# STM32H533 register map
File version: 1.3
CPU: CM33 r0p0, little endian, MPU, FPU, 4 interrupt priority bits
Registers are 32-bit, read-write, reset 0x0 unless marked. A register's access mark holds for its fields unless they carry their own. Offsets are from the block's base; [hi:lo] are bit positions; {n}, {i} and the like mark numbered series; 'fields as' and 'values as' point back to an identical list.

## SAU — Security Attribution Unit -- present only when the Security Extension (TrustZone) is implemented; absent entirely on a Non-secure-only/single-state part. RNR/RBAR/RLAR are further optional within that: only present when __SAUREGION_PRESENT=1, i.e. the implementation has at least one programmable SAU region (a part can implement the Security Extension with the whole memory map fixed Secure/Non-secure by IDAU alone and no SAU regions at all). Verified against CMSIS_6 core_cm23.h/core_cm33.h (identical on both profiles). SFSR/SFAR are modeled once, under SCB, since SAU_Type and SCB_Type both expose the same physical registers at the same address on Mainline -- CMSIS_6 now says so explicitly (SAU_Type's own SFSR/SFAR are commented "deprecated: use SCB->SFSR"/"SCB->SFAR"); Baseline has neither (no SecureFault handler exists there).
Base 0xE000EDD0
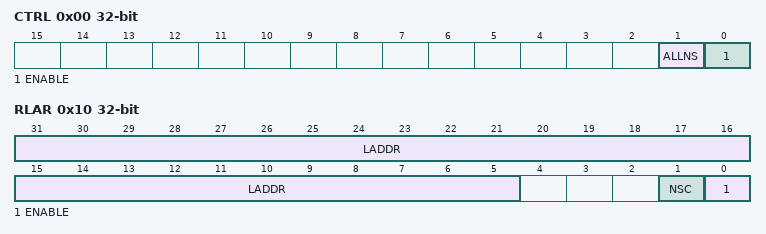
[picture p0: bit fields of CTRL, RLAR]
0x00 CTRL — SAU Control Register
  [1] ALLNS — All Non-secure -- forces the whole memory map Non-secure when SAU is disabled
  [0] ENABLE
0x04 TYPE ro — SAU Type Register
  [7:0] SREGION — Number of implemented SAU regions
0x08 RNR — SAU Region Number Register -- only present if __SAUREGION_PRESENT
  [7:0] REGION
0x0C RBAR — SAU Region Base Address Register -- only present if __SAUREGION_PRESENT
  [31:5] BADDR — Base address, 32-byte aligned
0x10 RLAR — SAU Region Limit Address Register -- only present if __SAUREGION_PRESENT
  [31:5] LADDR — Limit address, 32-byte aligned
  [1] NSC — Non-secure Callable
  [0] ENABLE

## SCnSCB — System Control and ID Registers not in the SCB address range: ICTR (Interrupt Controller Type Register), ACTLR (Auxiliary Control Register), and CPPWR (Coprocessor Power Control -- new in ARMv8-M Mainline). Verified against CMSIS_6 core_cm33.h. Absent entirely on ARMv8-M Baseline, same as ARMv6-M.
Base 0xE000E000
0x04 ICTR ro — Interrupt Controller Type Register
  [3:0] INTLINESNUM — (Number of 32-interrupt NVIC banks implemented) - 1: total external interrupts = (INTLINESNUM+1)*32
0x08 ACTLR — Auxiliary Control Register -- wholly IMPLEMENTATION DEFINED by the architecture, same as on ARMv7-M -- deliberately left with no fields.
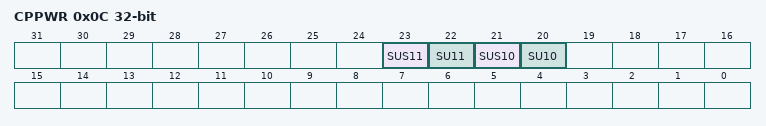
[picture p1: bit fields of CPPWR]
0x0C CPPWR — Coprocessor Power Control Register -- new in ARMv8-M Mainline; only meaningful if an FPU (coprocessors 10/11) is implemented.
  [23] SUS11 — Coprocessor 11 (FPU) power enable in Sleep -- only meaningful if an FPU is implemented
  [22] SU11 — Coprocessor 11 (FPU) power enable -- only meaningful if an FPU is implemented
  [21] SUS10 — Coprocessor 10 (FPU) power enable in Sleep -- only meaningful if an FPU is implemented
  [20] SU10 — Coprocessor 10 (FPU) power enable -- only meaningful if an FPU is implemented

## SysTick — SysTick Timer. Identical register set on every Cortex-M core (ARMv6-M through current ARMv8-M).
Base 0xE000E010
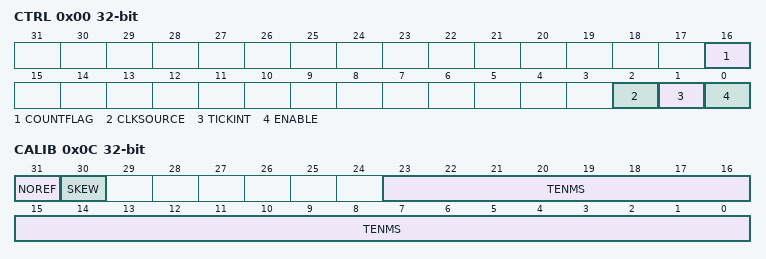
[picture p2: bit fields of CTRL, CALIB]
0x00 CTRL — SysTick Control and Status Register
  [16] COUNTFLAG ro, [2] CLKSOURCE, [1] TICKINT, [0] ENABLE
0x04 LOAD — SysTick Reload Value Register
  [23:0] RELOAD
0x08 VAL — SysTick Current Value Register. Any write clears it to 0 and clears COUNTFLAG.
  [23:0] CURRENT
0x0C CALIB ro — SysTick Calibration Value Register
  [31] NOREF, [30] SKEW, [23:0] TENMS

## TIM6 — TIM6 address block description
Base 0x40001000
Same registers: TIM6_S 0x50001000
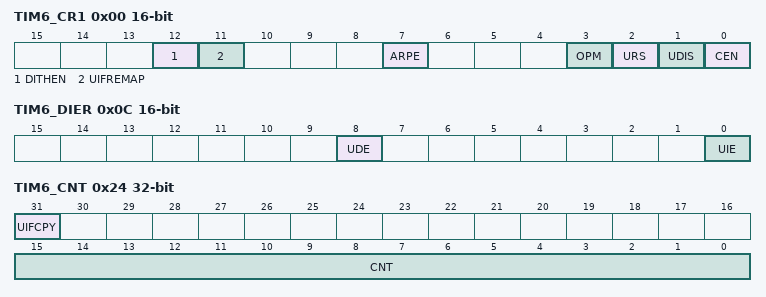
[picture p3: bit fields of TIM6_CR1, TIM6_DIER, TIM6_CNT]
0x00 TIM6_CR1 16-bit — TIM6 control register 1
  [12] DITHEN — Dithering enable
    0=Dithering disabled; 1=Dithering enabled
  [11] UIFREMAP — UIF status bit remapping
    0=No remapping; 1=Remapping enabled
  [7] ARPE — Auto-reload preload enable
    0=TIMx_ARR register is not buffered; 1=TIMx_ARR register is buffered
  [3] OPM — One-pulse mode
    0=Counter is not stopped at update event; 1=Counter stops counting at the next update event (clearing the CEN bit)
  [2] URS — Update request source
    0=Any of the following events generates an update interrupt or DMA request if enabled; 1=Only counter overflow/underflow generates an update interrupt or DMA request if enabled
  [1] UDIS — Update disable
    0=UEV enabled; 1=UEV disabled
  [0] CEN — Counter enable
    0=Counter disabled; 1=Counter enabled
0x04 TIM6_CR2 16-bit — TIM6 control register 2
  [6:4] MMS — Master mode selection
    0=Reset - the UG bit from the TIMx_EGR register is used as a trigger output (tim_trgo); 1=Enable - the Counter enable signal, tim_cnt_en, is used as a trigger output (tim_trgo); 2=Update - The update event is selected as a trigger output (tim_trgo)
0x0C TIM6_DIER 16-bit — TIM6 DMA/Interrupt enable register
  [8] UDE — Update DMA request enable
    0=Update DMA request disabled; 1=Update DMA request enabled
  [0] UIE — Update interrupt enable
    0=Update interrupt disabled; 1=Update interrupt enabled
0x10 TIM6_SR 16-bit — TIM6 status register
  [0] UIF — Update interrupt flag
    0=No update occurred; 1=Update interrupt pending
0x14 TIM6_EGR 16-bit wo — TIM6 event generation register
  [0] UG — Update generation
    0=No action; 1=Re-initializes the timer counter and generates an update of the registers
0x24 TIM6_CNT — TIM6 counter
  [31] UIFCPY ro — UIF copy
  [15:0] CNT — Counter value
0x28 TIM6_PSC 16-bit — TIM6 prescaler
  [15:0] PSC — Prescaler value
0x2C TIM6_ARR reset 0xFFFF — TIM6 auto-reload register
  [19:0] ARR — Auto-reload value

## TIM7 — TIM7 address block description
Base 0x40001400
Same registers: TIM7_S 0x50001400
Registers as TIM6 (with TIM6 read as TIM7).

## USBSRAM — USBSRAM address block description
Base 0x40016400
Same registers: USBSRAM_S 0x50016400
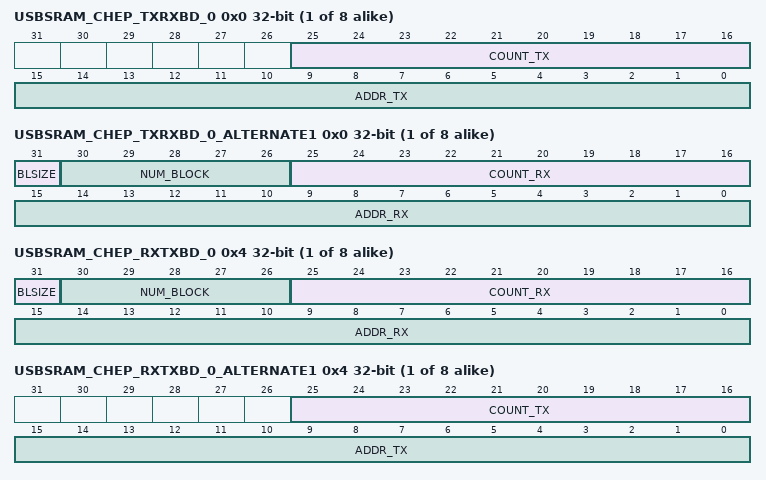
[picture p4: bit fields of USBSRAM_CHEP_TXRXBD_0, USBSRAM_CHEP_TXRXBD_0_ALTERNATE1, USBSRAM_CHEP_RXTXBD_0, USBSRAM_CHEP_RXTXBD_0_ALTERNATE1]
{0x0+8i} USBSRAM_CHEP_TXRXBD_{i} reset not defined (i=0..7) — Channel/endpoint transmit buffer descriptor {i}
  [25:16] COUNT_TX — Transmission byte count
  [15:0] ADDR_TX — Transmission buffer address
{0x0+8i} USBSRAM_CHEP_TXRXBD_{i}_ALTERNATE1 reset not defined (alternate view of USBSRAM_CHEP_TXRXBD_{i}) (i=0..7) — Channel/endpoint receive buffer descriptor {i}
  [31] BLSIZE — Block size
  [30:26] NUM_BLOCK — Number of blocks
  [25:16] COUNT_RX ro — Reception byte count
  [15:0] ADDR_RX — Reception buffer address
{0x4+8i} USBSRAM_CHEP_RXTXBD_{i} reset not defined (i=0..7) — Channel/endpoint receive buffer descriptor {i}
  fields as USBSRAM_CHEP_TXRXBD_0_ALTERNATE1
{0x4+8i} USBSRAM_CHEP_RXTXBD_{i}_ALTERNATE1 reset not defined (alternate view of USBSRAM_CHEP_RXTXBD_{i}) (i=0..7) — Channel/endpoint transmit buffer descriptor {i}
  fields as USBSRAM_CHEP_TXRXBD_0

## VREFBUF — VREFBUF address block description
Base 0x44007400
Same registers: VREFBUF_S 0x54007400
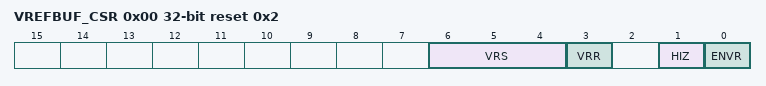
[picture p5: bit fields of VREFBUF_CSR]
0x00 VREFBUF_CSR reset 0x2 — VREFBUF control and status register
  [6:4] VRS — Voltage reference scale
  [3] VRR ro — Voltage reference buffer ready
    0=the voltage reference buffer output is not ready; 1=the voltage reference buffer output reached the requested level
  [1] HIZ — High impedance mode
    0=Vless thansub>REF+less than/sub> pin is internally connected to the voltage reference buffer output; 1=Vless thansub>REF+less than/sub> pin is high impedance
  [0] ENVR — Voltage reference buffer mode enable
    0=Internal voltage reference mode disable (external voltage reference mode); 1=Internal voltage reference mode (reference buffer enable or hold mode) enable
0x04 VREFBUF_CCR (reset mask 0xFFFFFF00) — VREFBUF calibration control register
  [5:0] TRIM — Trimming code

## WWDG — WWDG address block description
Base 0x40002C00
Same registers: WWDG_S 0x50002C00
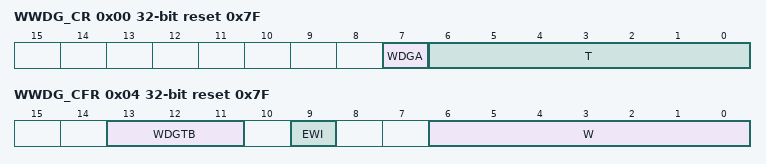
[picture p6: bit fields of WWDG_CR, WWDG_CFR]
0x00 WWDG_CR reset 0x7F — WWDG control register
  [7] WDGA — Activation bit
    0=Watchdog disabled; 1=Watchdog enabled
  [6:0] T — 7-bit counter (MSB to LSB)
0x04 WWDG_CFR reset 0x7F — WWDG configuration register
  [13:11] WDGTB — Timer base
    0=CK counter clock (PCLK div 4096) div 1; 1=CK counter clock (PCLK div 4096) div 2; 2=CK counter clock (PCLK div 4096) div 4; 3=CK counter clock (PCLK div 4096) div 8; 4=CK counter clock (PCLK div 4096) div 16; 5=CK counter clock (PCLK div 4096) div 32; 6=CK counter clock (PCLK div 4096) div 64; 7=CK counter clock (PCLK div 4096) div 128
  [9] EWI — Early wake-up interrupt enable
  [6:0] W — 7-bit window value
0x08 WWDG_SR — WWDG status register
  [0] EWIF — Early wake-up interrupt flag
